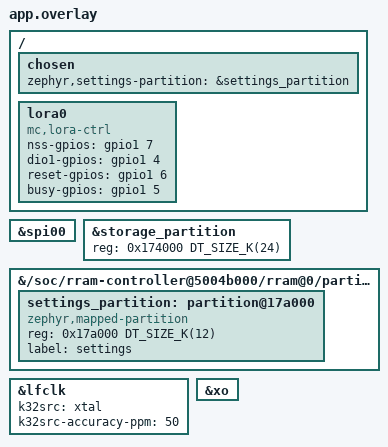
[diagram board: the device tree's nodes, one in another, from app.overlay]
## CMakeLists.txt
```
# Step 4e — full MeshCore companion (companion_radio MyMesh) on the Zephyr seams.
cmake_minimum_required(VERSION 3.20.0)
find_package(Zephyr REQUIRED HINTS $ENV{ZEPHYR_BASE})
project(mc_zephyr_companion)

get_filename_component(MC_ROOT "${CMAKE_CURRENT_SOURCE_DIR}/../.." ABSOLUTE)
set(CR       "${MC_ROOT}/examples/companion_radio")
set(ALFS     "${MC_ROOT}/arch/stm32/Adafruit_LittleFS_stm32/src")
set(RADIOLIB "$ENV{HOME}/Arduino/libraries/RadioLib/src")
set(CRYPTO   "$ENV{HOME}/Arduino/libraries/Crypto/src")
set(CAYENNE  "$ENV{HOME}/Arduino/libraries/CayenneLPP/src")
set(BASE64   "$ENV{HOME}/Arduino/libraries/base64/src")
set(RTCLIB   "$ENV{HOME}/Arduino/libraries/RTClib/src")
set(AJSON    "$ENV{HOME}/Arduino/libraries/ArduinoJson/src")
set(ED25519  "${MC_ROOT}/lib/ed25519")

# MeshCore core + helper set (mirrors the Arduino companion curation)
file(GLOB MC_CORE ${MC_ROOT}/src/*.cpp)
set(MC_HELPERS
  ${MC_ROOT}/src/helpers/BaseChatMesh.cpp
  ${MC_ROOT}/src/helpers/TransportKeyStore.cpp
  ${MC_ROOT}/src/helpers/IdentityStore.cpp
  ${MC_ROOT}/src/helpers/RegionMap.cpp
  ${MC_ROOT}/src/helpers/ClientACL.cpp
  ${MC_ROOT}/src/helpers/CommonCLI.cpp
  ${MC_ROOT}/src/helpers/AdvertDataHelpers.cpp
  ${MC_ROOT}/src/helpers/TxtDataHelpers.cpp
  ${MC_ROOT}/src/helpers/StaticPoolPacketManager.cpp
  ${MC_ROOT}/src/helpers/radiolib/RadioLibWrappers.cpp)

# companion firmware
set(MC_APP ${CR}/MyMesh.cpp ${CR}/DataStore.cpp)

# third-party (generic/non-Arduino mode for RadioLib)
file(GLOB_RECURSE RL_SOURCES ${RADIOLIB}/*.cpp)
list(FILTER RL_SOURCES EXCLUDE REGEX "/hal/Arduino/")
file(GLOB CRYPTO_SRC ${CRYPTO}/*.cpp ${CRYPTO}/*.c)
file(GLOB BASE64_SRC ${BASE64}/*.cpp)
# CayenneLPP + RTClib are shimmed in compat/ (header-only) — real libs pull STL/I2C.
file(GLOB ED_SRC ${ED25519}/*.c)
set(ALFS_SRC ${ALFS}/Adafruit_LittleFS.cpp ${ALFS}/Adafruit_LittleFS_File.cpp
             ${ALFS}/littlefs/lfs.c ${ALFS}/littlefs/lfs_util.c)

target_sources(app PRIVATE
  src/main.cpp src/target.cpp src/zephyr_internal_fs.cpp src/serial_ble_interface.cpp
  ${MC_CORE} ${MC_HELPERS} ${MC_APP}
  ${RL_SOURCES} ${CRYPTO_SRC} ${BASE64_SRC} ${ED_SRC} ${ALFS_SRC})

target_include_directories(app PRIVATE
  compat src ${MC_ROOT}/src ${CR} ${ALFS}
  ${RADIOLIB} ${CRYPTO} ${BASE64} ${ED25519})

target_compile_definitions(app PRIVATE
  NRF54_PLATFORM=1 MESH_DEBUG=1 RADIOLIB_GODMODE=1 MAX_GROUP_CHANNELS=8 MAX_CONTACTS=100 BLE_PIN_CODE=123456
  LFS_NO_ASSERT   # mount-fail (e.g. stale/repartitioned region) -> graceful format, not abort()
  # App TX-power slider max + firmware input check. Pin to the LR2021's absolute (sub-GHz LF)
  # PA ceiling of 22 dBm, INDEPENDENT of the band/boot default, so a 2.4 GHz build still allows
  # 22 once tuned back to sub-GHz. The real per-band limit (HF caps at +12) is enforced at the
  # radio layer by clamp_tx_for_band() in target.cpp. (Otherwise MAX would follow LORA_TX_POWER,
  # which MC_BAND_2G4 sets to 12 -> the app would be stuck at 12 even on 869 MHz.)
  MAX_LORA_TX_POWER=22)

# 2.4 GHz band: build with `-DMC_BAND_2G4=ON` (e.g. west build -- -DMC_BAND_2G4=ON) to boot on
# the LR2021's 2.4 GHz preset (target.h: 2450 MHz / 500 kHz / SF8 / CR5, TX clamped to +12 dBm)
# instead of the default 865 MHz sub-GHz. The app has no 2.4 GHz preset, so this is how to put
# the node on 2.4 GHz for the over-the-air RF test (the choice then persists in prefs).
option(MC_BAND_2G4 "Boot on the 2.4 GHz LoRa preset instead of sub-GHz" OFF)
option(MC_LOW_POWER "Battery build: LR2021 RX duty cycling + sleepy main loop" OFF)
# Side detectors: extra spreading factors the LR2021 receives in parallel on the node's
# channel (comma list, all above the primary SF and within +4; invalid ones are skipped
# when the app changes the SF). A node heard on a side SF is answered on that SF.
set(MC_SIDE_SFS "8" CACHE STRING "LR2021 side-detector SFs, e.g. 8,9,11 (empty = none)")
target_compile_definitions(app PRIVATE MC_SIDE_SFS="${MC_SIDE_SFS}")
if(MC_LOW_POWER)
  target_compile_definitions(app PRIVATE MC_LOW_POWER=1)
endif()
# LoRa boot params must be global -D flags (mirroring platformio.ini), not header
# defines: core headers (e.g. RadioLibWrappers.h getSpreadingFactor) expand LORA_SF
# in translation units that never include target.h. Keep in sync with the presets
# documented in src/target.h.
if(MC_BAND_2G4)
  target_compile_definitions(app PRIVATE MC_BAND_2G4=1
    LORA_FREQ=2450.0f LORA_BW=500.0f LORA_SF=8 LORA_CR=5 LORA_TX_POWER=12)
  message(STATUS "MeshCore: building for 2.4 GHz band (2450 MHz / 500 kHz / SF8 / CR5)")
else()
  target_compile_definitions(app PRIVATE
    LORA_FREQ=869.432f LORA_BW=62.5f LORA_SF=7 LORA_CR=5 LORA_TX_POWER=22)
endif()
```

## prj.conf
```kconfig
# Step 4e — full MeshCore companion on Zephyr.
CONFIG_BT=y
CONFIG_BT_PERIPHERAL=y
CONFIG_BT_DEVICE_NAME="MeshCore"
CONFIG_BT_DEVICE_NAME_DYNAMIC=y
CONFIG_BT_DEVICE_NAME_MAX=40
CONFIG_BT_SMP=y
CONFIG_BT_BONDABLE=y
CONFIG_BT_APP_PASSKEY=y
# BT_MAX_PAIRED defaults to 1 (= BT_MAX_CONN). Phone A bonds -> the single bond slot fills;
# phone B then connects but its (MITM-enforced) pairing has no free slot and FAILS, so B can't
# reach the encryption-gated NUS -> "needs a hard reset to connect another device". Let a new
# pairing recycle the oldest bond instead. (Bonds are RAM-only here, BT_SETTINGS off, so this
# just means each new phone re-pairs cleanly.)
CONFIG_BT_KEYS_OVERWRITE_OLDEST=y
# NUS: we define our own encryption-gated NUS GATT service in serial_ble_interface.cpp
# (so the central drives pairing). Zephyr's built-in NUS is disabled to avoid a duplicate
# service with the same UUIDs.
# CONFIG_BT_ZEPHYR_NUS=y
CONFIG_BT_L2CAP_TX_MTU=247
CONFIG_BT_BUF_ACL_TX_SIZE=251
CONFIG_BT_BUF_ACL_RX_SIZE=251
# At boot the first BLE advertising event collides with the bring-up storm (LR2021 SPI
# init + LittleFS mount + mesh begin), so the SW-split controller's prepare callback runs
# tens of ms late on that one event. BT_CTLR_ASSERT_OVERHEAD_START (default y, a debug aid)
# turns that latency into a FATAL assert (lll_adv.c LL_ASSERT_OVERHEAD), which crashed the
# whole device -- taking the LoRa mesh down with it (no advert RX, looked like a reset loop).
# Disabling it restores the controller's designed behaviour: gracefully skip the delayed
# event (radio_disable + -ECANCELED) and keep running.
# NOTE: ASSERT_OVERHEAD_START lives in the controller's "Advanced features" menu, which is
# `visible if BT_CTLR_ADVANCED_FEATURES`. Without that gate enabled the prompt is hidden and
# a `=n` is silently ignored (symbol stays at its default y). Enable the gate (visibility
# only, no other behaviour change) so the override below actually takes effect.
CONFIG_BT_CTLR_ADVANCED_FEATURES=y
CONFIG_BT_CTLR_ASSERT_OVERHEAD_START=n

CONFIG_FLASH=y
CONFIG_FLASH_MAP=y
# RRAM is byte-alterable and writes (no long erase like NOR flash). The flash driver
# otherwise defaults to RADIO_SYNC_TICKER (because BT_LL_SW_SPLIT), which schedules every
# write into BLE idle timeslots. While connected that dribbles a savePrefs() out one tiny
# window per connection event => a fixed 24s per settings write. Disable radio sync: RRAM
# writes are short enough to run synchronously without disturbing the radio (also bumps the
# RRAM write-buffer 1 -> 32, fewer commits).
CONFIG_SOC_FLASH_NRF_RADIO_SYNC_NONE=y

# Bond persistence DISABLED: on the vanilla open-source controller it broke bonded
# reconnect (phone re-pairs on every reconnect -> disconnect loop) and earlier overflowed
# the bond-save stack. Each connect is a fresh pair (the known-good Android-working flow).
# Robust persistence needs NCS + Nordic SoftDevice Controller (handles bonded-RPA reconnect).
# Persistent bonds on the ZMS backend (RRAM is byte-alterable, no erase - ZMS,
# not NVS, is the settings backend for it), in the 12 KB settings_partition.
CONFIG_BT_SETTINGS=y
CONFIG_SETTINGS=y
CONFIG_FLASH_MAP=y
CONFIG_ZMS=y
CONFIG_SETTINGS_ZMS=y
CONFIG_BT_MAX_PAIRED=3
CONFIG_BT_MAX_CONN=1
CONFIG_BT_SETTINGS_CCC_LAZY_LOADING=y
CONFIG_BT_SETTINGS_CCC_STORE_ON_WRITE=y
# (stacks kept harmless, headroom for the BT/workqueue paths)
CONFIG_BT_RX_STACK_SIZE=8192
CONFIG_SYSTEM_WORKQUEUE_STACK_SIZE=8192

CONFIG_GPIO=y
CONFIG_SPI=y
CONFIG_CPP=y
CONFIG_STD_CPP17=y
CONFIG_CPP_EXCEPTIONS=n
CONFIG_PRINTK=y
CONFIG_CBPRINTF_FP_SUPPORT=y
CONFIG_MAIN_STACK_SIZE=16384
CONFIG_HEAP_MEM_POOL_SIZE=16384
CONFIG_FPU=y
CONFIG_REBOOT=y
CONFIG_ENTROPY_GENERATOR=y

# A fatal error (e.g. the BLE controller assert race) must reboot the node, not halt it.
CONFIG_RESET_ON_FATAL_ERROR=y

# Let the SoC idle between events (the main loop now blocks on a semaphore)
# CONFIG_PM=y  (bisect: suspected of breaking SPI/console once the loop blocks)

# BLE link robustness (2026-09-11): the nRF54L15 radio can do +8 dBm (default 0), and the
# peripheral-preferred supervision timeout defaulted to 420 ms, so any half-second fade at a
# few metres dropped the link and the web app then needed a manual reconnect. 4 s tolerates
# fades; the interval preference (30-50 ms) is unchanged.
CONFIG_BT_CTLR_TX_PWR_PLUS_8=y
CONFIG_BT_PERIPHERAL_PREF_TIMEOUT=400
```

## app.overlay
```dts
/*
 * LR2021 wiring on the XIAO nRF54L15 (matches variants/xiao_nrf54l15/target.h):
 *   SPI  = spi00 (xiao_spi): SCK=P2.1(D8) MOSI=P2.2(D10) MISO=P2.4(D9)
 *   NSS  = P1.7 (D3)   DIO1 = P1.4 (D0)   RESET = P1.6 (D2)   BUSY = P1.5 (D1)
 *
 * RadioLib drives NSS itself (digitalWrite), so the SPI controller is used WITHOUT
 * a hardware CS. The four control pins are plain GPIOs (flags=0 / active-high; the
 * HAL uses raw ops so RadioLib's LOW/HIGH map to physical levels, as on Arduino).
 */
&spi00 {
	status = "okay";
};

/*
 * Split the 36 KB RRAM storage region (0x174000..0x17D000): MeshCore's LittleFS keeps
 * 24 KB; a 12 KB NVS settings partition holds BLE bonds (CONFIG_BT_SETTINGS) so the app
 * doesn't have to re-pair after every reboot.
 */
&storage_partition {
	reg = <0x174000 DT_SIZE_K(24)>;
};

/* add the settings partition as a sibling under the existing fixed-partitions node */
&{/soc/rram-controller@5004b000/rram@0/partitions} {
	settings_partition: partition@17a000 {
		compatible = "zephyr,mapped-partition";
		reg = <0x17a000 DT_SIZE_K(12)>;
		label = "settings";
	};
};

/ {
	chosen {
		zephyr,settings-partition = &settings_partition;
	};

	lora0: lora0 {
		compatible = "mc,lora-ctrl";
		nss-gpios   = <&gpio1 7 0>;
		dio1-gpios  = <&gpio1 4 0>;
		reset-gpios = <&gpio1 6 0>;
		busy-gpios  = <&gpio1 5 0>;
	};
};

/* Zephyr >= 4.5: the BLE controller reads its sleep-clock accuracy from the lfclk
 * node, which the SoC dtsi leaves disabled and the XIAO board files do not enable.
 * The board has a 32.768 kHz crystal (the board dts enables &lfxo). */
&lfclk {
	status = "okay";
	k32src = "xtal";
	k32src-accuracy-ppm = <50>;
};
&xo {
	status = "okay";
};
```

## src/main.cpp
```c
/*
 * Step 4e: the full MeshCore companion on Zephyr. Wires companion_radio's MyMesh +
 * DataStore onto the proven Zephyr seams: radio (target.cpp / RadioLib+ZephyrHal),
 * filesystem (InternalFS / flash_area), and serial = the bonded bt_nus SerialBLEInterface.
 * The phone app pairs (level 4, fixed PIN), then talks the companion protocol over NUS.
 */
#include <zephyr/kernel.h>
#include <zephyr/sys/printk.h>
#include <string.h>
#include <Arduino.h>
#include <target.h>
#include <helpers/nrf54/InternalFileSystem.h>
#include <helpers/SimpleMeshTables.h>
#include "serial_ble_interface.h"
#include "MyMesh.h"   /* examples/companion_radio (on the include path) */

/* Wake-ups for the main loop: the LoRa DIO interrupt and BLE data give this
 * semaphore; otherwise the loop sleeps (MC_LOOP_SLEEP_MS) and the SoC idles. */
K_SEM_DEFINE(mc_wake_sem, 0, 1);
extern "C" void mc_wake(void) { k_sem_give(&mc_wake_sem); }
#ifndef MC_LOOP_SLEEP_MS
#ifdef MC_LOW_POWER
#define MC_LOOP_SLEEP_MS 25
#else
#define MC_LOOP_SLEEP_MS 2
#endif
#endif

SerialShim Serial;

StdRNG fast_rng;
SimpleMeshTables tables;
DataStore store(InternalFS, rtc_clock);

/* Stock MyMesh plus LR2021 time-of-flight ranging (RangingControl.h): answer a
 * neighbour's ranging request as subordinate; range a contact on a private app
 * frame 0xF0 (the BLE interface keeps those aside for us). */
class RangingMesh : public MyMesh {
public:
	using MyMesh::MyMesh;
	RangingRequest defaults{{0, 0, 0, 0}, 2450000000u, 500000, 8, 10, 20438};

	void onControlDataRecv(mesh::Packet* packet) override
	{
		RangingRequest req;
		printk("control packet: type %02x len %u\n", packet->payload[0], packet->payload_len);
		if (rangingDecodeRequest(packet->payload, packet->payload_len, req)) {
			if (memcmp(req.peer, self_id.pub_key, 4) != 0) return;
			printk("ranging: request from a neighbour (%u Hz bw %u sf %u, %u exchanges)\n", req.freq_hz, req.bw_hz, req.sf, req.count);
			NodePrefs* p = getNodePrefs();
			radio_range_subordinate(req, rangingAddrFromPubKey(self_id.pub_key), p->freq, p->bw, p->sf, p->cr);
			return;
		}
		MyMesh::onControlDataRecv(packet);
	}

	void rangeContact(const uint8_t* peer_pubkey, uint8_t count, RangingResult& res)
	{
		RangingRequest req = defaults;
		memcpy(req.peer, peer_pubkey, 4);
		if (count) req.count = count;
		uint8_t payload[RANGING_REQ_LEN];
		rangingEncodeRequest(req, payload);
		mesh::Packet* pkt = createControlData(payload, RANGING_REQ_LEN);
		if (!pkt) { res.status = 3; return; }
		pkt->header &= ~PH_ROUTE_MASK;
		pkt->header |= ROUTE_TYPE_DIRECT;
		pkt->path_len = 0;
		uint8_t raw[MAX_TRANS_UNIT + 8];
		int len = pkt->writeTo(raw);
		releasePacket(pkt);
		if (!radio_driver.startSendRaw(raw, len)) { res.status = 3; return; }
		int64_t t0 = k_uptime_get();
		while (!radio_driver.isSendComplete() && k_uptime_get() - t0 < 2000) { k_msleep(2); }
		radio_driver.onSendFinished();
		k_msleep(RANGING_SETUP_MS);
		NodePrefs* p = getNodePrefs();
		radio_range_manager(req, rangingAddrFromPubKey(peer_pubkey), res, p->freq, p->bw, p->sf, p->cr);
	}
};
RangingMesh the_rmesh(radio_driver, fast_rng, rtc_clock, tables, store);
#define the_mesh the_rmesh

int main(void)
{
	printk("\n=== MeshCore companion on Zephyr (board=%s) ===\n", CONFIG_BOARD);

	board.begin();
	if (!radio_init()) { printk("radio_init FAILED\n"); return 0; }
#ifdef MC_LOW_POWER
	radio_set_low_power(true);
	printk("low-power build: LR2021 RX duty cycling, %d ms loop sleep\n", MC_LOOP_SLEEP_MS);
#endif
	fast_rng.begin(radio_get_rng_seed());
	if (!InternalFS.begin()) { printk("InternalFS FAILED\n"); return 0; }
	store.begin();
	the_mesh.begin(false);   /* no display (loads prefs from /new_prefs) */

	/* DEBUG: did the node name survive the last power cycle? On a cold boot this should show
	 * the previously-set name and exists=1; if it shows the default name / exists=0 the prefs
	 * file was lost (reformat or never persisted). Paired with the "FS: mounted OK/FAILED" line. */
	printk("PREFS: cold boot -> /new_prefs exists=%d, node_name='%s'\n",
	       InternalFS.exists("/new_prefs"), the_mesh.getNodePrefs()->node_name);

	char name[48];
	snprintf(name, sizeof(name), "%s%s", BLE_NAME_PREFIX, the_mesh.getNodePrefs()->node_name);
#ifndef MC_NO_BLE
	ble.begin(name, the_mesh.getBLEPin());
#else
	printk("BLE stack not started (MC_NO_BLE RF interference test build)\n");
#endif
	the_mesh.startInterface(ble);
	printk("companion up: '%s' pin %lu — connect from the MeshCore app\n",
	       name, (unsigned long)the_mesh.getBLEPin());

	while (1) {
		the_mesh.loop();
		{
			uint8_t frame[64];
			size_t n = ble.takePrivateFrame(frame, sizeof(frame));
			if (n >= 34 && frame[0] == RANGING_CMD_CODE) {
				RangingResult res;
				the_mesh.rangeContact(&frame[1], frame[33], res);
				uint8_t out[16];
				ble.writeFrame(out, rangingEncodeResult(res, out));
			}
		}
		rtc_clock.tick();
		sensors.loop();

		/* A rename from the app (CMD_SET_ADVERT_NAME) only updates prefs; push it to BLE so
		 * the advertised/GAP name follows without a reboot. */
		char cur[48];
		snprintf(cur, sizeof(cur), "%s%s", BLE_NAME_PREFIX, the_mesh.getNodePrefs()->node_name);
		if (strcmp(cur, name) != 0) {
			strcpy(name, cur);
			ble.setDeviceName(name);
			/* DEBUG: confirm the rename reached the FS (savePrefs ran in the CMD handler).
			 * exists=1 means /new_prefs was (re)written; if it's still 0 the save never landed. */
			printk("PREFS: rename -> '%s', /new_prefs exists=%d\n",
			       the_mesh.getNodePrefs()->node_name, InternalFS.exists("/new_prefs"));
		}

		k_sem_take(&mc_wake_sem, K_MSEC(MC_LOOP_SLEEP_MS));   /* radio IRQ / BLE data wake us early */
	}
	return 0;
}
```

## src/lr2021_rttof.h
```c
/*
 * LR2021 RTToF (time-of-flight ranging) on top of RadioLib, for the Zephyr
 * companion. Same sequence as lr2021_serial's rng commands / Semtech's USP demo:
 * packet type RTToF, the LoRa modulation re-programmed, the PLL frequency-step
 * register workaround, Tx->Rx delay indicator, then SetTx (manager) or continuous
 * SetRx (subordinate). Distance [m] = raw * 150 / (4096 * BW_MHz).
 */
#pragma once
#include <zephyr/kernel.h>
#include <helpers/radiolib/CustomLR2021.h>
#include "RangingControl.h"

static int16_t rttof_setup(CustomLR2021& r, bool subordinate, uint32_t addr, uint32_t delay, int8_t pwr, uint8_t irq_dio) {
  r.standby();
  int16_t st = r.setPacketType(RADIOLIB_LR2021_PACKET_TYPE_RTTOF);
  if (st == RADIOLIB_ERR_NONE) st = r.setLoRaModulationParams(r.sfCode(), r.bwCode(), r.crCode(), r.ldroCode());
  if (st == RADIOLIB_ERR_NONE) {          // workaround: truncate the PLL frequency step
    uint32_t v = 0; st = r.readRegMem32(0x00F40144, &v, 1);
    if (st == RADIOLIB_ERR_NONE) { v &= ~0x7Fu; st = r.writeRegMem32(0x00F40144, &v, 1); }
  }
  if (st == RADIOLIB_ERR_NONE && !subordinate) st = r.setOutputPower(pwr);
  if (st == RADIOLIB_ERR_NONE) st = r.setLoRaPacketParams(12, RADIOLIB_LRXXXX_LORA_HEADER_EXPLICIT, 7, RADIOLIB_LRXXXX_LORA_CRC_ENABLED, 0);
  if (st == RADIOLIB_ERR_NONE) st = r.setLoRaSyncword(RADIOLIB_LR2021_LORA_SYNC_WORD_PRIVATE);
  uint32_t irq = subordinate ? (RADIOLIB_LR2021_IRQ_TIMEOUT | RADIOLIB_LR2021_IRQ_RNG_REQ_DIS | RADIOLIB_LR2021_IRQ_RNG_RESP_DONE | RADIOLIB_LR2021_IRQ_RNG_REQ_VALID)
                             : (RADIOLIB_LR2021_IRQ_RNG_EXCH_VALID | RADIOLIB_LR2021_IRQ_RNG_TIMEOUT | RADIOLIB_LR2021_IRQ_TIMEOUT);
  if (st == RADIOLIB_ERR_NONE) st = r.setDioIrqConfig(irq_dio, irq);
  if (st == RADIOLIB_ERR_NONE) st = r.setRangingTxRxDelay(delay);
  if (st == RADIOLIB_ERR_NONE) st = r.setRangingParams(false, 15);
  if (st == RADIOLIB_ERR_NONE) st = subordinate ? r.setRangingAddr(addr, 4) : r.setRangingReqAddr(addr);
  if (st == RADIOLIB_ERR_NONE) st = r.clearIrqState(RADIOLIB_LR2021_IRQ_ALL);
  return st;
}

// Apply the ranging radio parameters in LoRa mode first (RadioLib caches the codes).
static int16_t rttof_tune(CustomLR2021& r, const RangingRequest& req, int8_t pwr) {
  r.standby();
  int16_t st = r.setFrequency(req.freq_hz / 1000000.0f);
  if (st == RADIOLIB_ERR_NONE) st = r.setBandwidth(req.bw_hz / 1000.0f);
  if (st == RADIOLIB_ERR_NONE) st = r.setSpreadingFactor(req.sf);
  if (st == RADIOLIB_ERR_NONE) st = r.setCodingRate(5);
  if (st == RADIOLIB_ERR_NONE) st = r.setRxBoostedGainMode(7);   // also selects the band's RX path
  if (st == RADIOLIB_ERR_NONE) st = r.setOutputPower(pwr);        // and the band's PA
  return st;
}

// Answer ranging requests for `window_ms`. Blocks. Leaves the chip in standby, packet type LoRa.
static bool rttof_subordinate(CustomLR2021& r, const RangingRequest& req, uint32_t my_addr, uint8_t irq_dio, uint32_t window_ms, int* answered) {
  int8_t pwr = req.freq_hz > 1500000000u ? 10 : 14;
  if (rttof_tune(r, req, pwr) != RADIOLIB_ERR_NONE) return false;
  if (rttof_setup(r, true, my_addr, req.delay, pwr, irq_dio) != RADIOLIB_ERR_NONE) return false;
  int n = 0;
  int64_t end = k_uptime_get() + window_ms;
  r.setRx(RADIOLIB_LR2021_RX_TIMEOUT_INF);
  while (k_uptime_get() < end) {
    uint32_t irq = r.getIrqFlags();
    if (irq & (RADIOLIB_LR2021_IRQ_RNG_RESP_DONE | RADIOLIB_LR2021_IRQ_RNG_REQ_DIS | RADIOLIB_LR2021_IRQ_TIMEOUT)) {
      if (irq & RADIOLIB_LR2021_IRQ_RNG_RESP_DONE) n++;
      r.clearIrqState(RADIOLIB_LR2021_IRQ_ALL);
      r.setRx(RADIOLIB_LR2021_RX_TIMEOUT_INF);
    }
    k_msleep(2);
  }
  r.standby();
  r.clearTxFifo(); r.clearRxFifo();
  r.setPacketType(RADIOLIB_LR2021_PACKET_TYPE_LORA);
  if (answered) *answered = n;
  return true;
}

// Run `count` exchanges as manager against `peer_addr`. Blocks. Leaves the chip in standby, packet type LoRa.
static bool rttof_manager(CustomLR2021& r, const RangingRequest& req, uint32_t peer_addr, uint8_t irq_dio, RangingResult& res) {
  res = RangingResult(); res.count = req.count;
  int8_t pwr = req.freq_hz > 1500000000u ? 10 : 14;
  if (rttof_tune(r, req, pwr) != RADIOLIB_ERR_NONE || rttof_setup(r, false, peer_addr, req.delay, pwr, irq_dio) != RADIOLIB_ERR_NONE) { res.status = 2; return false; }
  static const uint8_t payload[7] = {0x52, 0x4e, 0x47, 0, 0, 0, 0};
  static int32_t raws[200]; int n = 0;
  float bw_mhz = req.bw_hz / 1000000.0f;
  for (int i = 0; i < req.count && i < 200; i++) {
    r.standby(); r.clearIrqState(RADIOLIB_LR2021_IRQ_ALL);
    r.clearTxFifo();                                  // stale FIFO bytes corrupt the next LoRa TX
    r.writeRadioTxFifo(payload, sizeof(payload));
    if (r.setTx(0) != RADIOLIB_ERR_NONE) break;
    int64_t t0 = k_uptime_get(); uint32_t irq = 0;
    while (k_uptime_get() - t0 < 1500) {
      irq = r.getIrqFlags();
      if (irq & (RADIOLIB_LR2021_IRQ_RNG_EXCH_VALID | RADIOLIB_LR2021_IRQ_RNG_TIMEOUT | RADIOLIB_LR2021_IRQ_TIMEOUT)) break;
      k_msleep(1);
    }
    if (irq & RADIOLIB_LR2021_IRQ_RNG_EXCH_VALID) {
      uint32_t r1 = 0, r2 = 0; uint8_t rs = 0;
      r.getRangingResult(RADIOLIB_LR2021_RANGING_RESULT_TYPE_RAW, &r1, &rs, &r2);
      int32_t v = (int32_t)r1; if (v >= (1 << 23)) v -= (1 << 24);
      raws[n++] = v;
    }
    r.clearIrqState(RADIOLIB_LR2021_IRQ_ALL);
    k_msleep(50);
  }
  r.standby();
  r.clearTxFifo(); r.clearRxFifo();
  r.setPacketType(RADIOLIB_LR2021_PACKET_TYPE_LORA);
  if (!n) { res.status = 1; return false; }
  for (int i = 1; i < n; i++) { int32_t v = raws[i]; int j = i - 1; while (j >= 0 && raws[j] > v) { raws[j + 1] = raws[j]; j--; } raws[j + 1] = v; }
  auto cm = [&](int32_t raw) { return (int32_t)(raw * 150.0f / (4096.0f * bw_mhz) * 100.0f); };
  res.status = 0; res.valid = (uint8_t)n;
  res.median_cm = cm(raws[n / 2]); res.min_cm = cm(raws[0]); res.max_cm = cm(raws[n - 1]);
  return true;
}
```

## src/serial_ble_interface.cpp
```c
#include "serial_ble_interface.h"
extern "C" void mc_wake(void);   /* main loop wake-up (main.cpp) */
#include <zephyr/sys/printk.h>
#include <zephyr/bluetooth/bluetooth.h>
#include <zephyr/bluetooth/conn.h>
#include <zephyr/bluetooth/gatt.h>
#include <zephyr/bluetooth/uuid.h>
#include <zephyr/settings/settings.h>
#include <string.h>

SerialBLEInterface ble;

#ifndef BLE_DBG
#define BLE_DBG(...) printk("BLE: " __VA_ARGS__)
#endif

#ifndef MC_BLE_VERBOSE
#define MC_BLE_VERBOSE 1     /* dump every companion frame in/out */
#endif

#if MC_BLE_VERBOSE
static void mc_dump(const char *dir, const uint8_t *b, uint16_t len)
{
	printk("[%8lld] %s code=%-3u len=%-3u :", (long long)k_uptime_get(), dir, len ? b[0] : 0, len);
	for (uint16_t i = 0; i < len && i < 28; i++) printk(" %02x", b[i]);
	printk("%s\n", len > 28 ? " ..." : "");
}
#else
#define mc_dump(d, b, l)
#endif

/* advertising payload: name + NUS 128-bit UUID (so the MeshCore app finds us).
 * g_ad[1] (the scan-list name) is rewritten at begin() from the runtime node name;
 * CONFIG_BT_DEVICE_NAME is only a placeholder. bt_set_name() sets the GAP Device Name
 * *characteristic* but NOT this advertising payload, so without the rewrite the node
 * always advertised the static "MeshCore" regardless of the configured node name. */
static char g_adv_name[27];   /* 31B adv - 3B flags - 2B AD header => 26 name chars + NUL */
static struct bt_data g_ad[] = {
	BT_DATA_BYTES(BT_DATA_FLAGS, (BT_LE_AD_GENERAL | BT_LE_AD_NO_BREDR)),
	BT_DATA(BT_DATA_NAME_COMPLETE, CONFIG_BT_DEVICE_NAME, sizeof(CONFIG_BT_DEVICE_NAME) - 1),
};
static const struct bt_data g_sd[] = {
	BT_DATA_BYTES(BT_DATA_UUID128_ALL,
		BT_UUID_128_ENCODE(0x6E400001, 0xB5A3, 0xF393, 0xE0A9, 0xE50E24DCCA9E)),
};

/* custom Nordic-UART service, ENCRYPTION-GATED so the *central* drives pairing
 * Zephyr's stock bt_nus characteristics are PERM_NONE, which forced us to send a peripheral
 * SMP Security Request on connect; iOS/Windows respond to that by pairing then dropping &
 * reconnecting. Gating the RX-write and the TX CCC on *authenticated* encryption makes the
 * central initiate MITM (passkey) pairing on first access and stay on the same link. */
static struct bt_uuid_128 nus_srv_uuid = BT_UUID_INIT_128(
	BT_UUID_128_ENCODE(0x6E400001, 0xB5A3, 0xF393, 0xE0A9, 0xE50E24DCCA9E));
static struct bt_uuid_128 nus_tx_uuid = BT_UUID_INIT_128(   /* notify: NODE->APP */
	BT_UUID_128_ENCODE(0x6E400003, 0xB5A3, 0xF393, 0xE0A9, 0xE50E24DCCA9E));
static struct bt_uuid_128 nus_rx_uuid = BT_UUID_INIT_128(   /* write:  APP->NODE */
	BT_UUID_128_ENCODE(0x6E400002, 0xB5A3, 0xF393, 0xE0A9, 0xE50E24DCCA9E));

static ssize_t nus_rx_write(struct bt_conn *conn, const struct bt_gatt_attr *attr,
			    const void *buf, uint16_t len, uint16_t offset, uint8_t flags)
{
	(void)conn; (void)attr; (void)offset; (void)flags;
	ble._onRx(buf, len);
	return len;
}
static void nus_tx_ccc_changed(const struct bt_gatt_attr *attr, uint16_t value) { (void)attr; (void)value; }

/* attrs[0]=svc [1]=TX chrc [2]=TX value [3]=CCC [4]=RX chrc [5]=RX value;
 * notify on attrs[1] (mirrors Zephyr's bt_nus_send). */
BT_GATT_SERVICE_DEFINE(nus_svc,
	BT_GATT_PRIMARY_SERVICE(&nus_srv_uuid),
	BT_GATT_CHARACTERISTIC(&nus_tx_uuid.uuid, BT_GATT_CHRC_NOTIFY,
			       BT_GATT_PERM_NONE, NULL, NULL, NULL),
	BT_GATT_CCC(nus_tx_ccc_changed, BT_GATT_PERM_READ | BT_GATT_PERM_WRITE_AUTHEN),
	BT_GATT_CHARACTERISTIC(&nus_rx_uuid.uuid,
			       BT_GATT_CHRC_WRITE | BT_GATT_CHRC_WRITE_WITHOUT_RESP,
			       BT_GATT_PERM_WRITE_AUTHEN, NULL, nus_rx_write, NULL),
);

/* C BLE callbacks bridging to the single `ble` instance */
static void cb_connected(struct bt_conn *conn, uint8_t err)
{
	if (err) { BLE_DBG("connect failed 0x%02x\n", err); return; }
	BLE_DBG("connected\n");
	ble._onConnect(conn);
	/* Do NOT initiate security here. The NUS characteristics are gated on authenticated
	 * encryption, so the CENTRAL triggers MITM pairing on first access and keeps the link.
	 * A peripheral-initiated Security Request is what made iOS/Windows pair-then-reconnect. */
}
static void cb_disconnected(struct bt_conn *conn, uint8_t reason)
{
	BLE_DBG("disconnected 0x%02x\n", reason);
	ble._onDisconnect(conn);
}
static void cb_security_changed(struct bt_conn *conn, bt_security_t level, enum bt_security_err err)
{
	BLE_DBG("security level %d err %d\n", level, err);
	ble._onSecured(conn, err == BT_SECURITY_ERR_SUCCESS && level >= BT_SECURITY_L2);
}
BT_CONN_CB_DEFINE(conn_cbs) = {
	.connected = cb_connected,
	.disconnected = cb_disconnected,
	.security_changed = cb_security_changed,
};

static void auth_passkey_display(struct bt_conn *conn, unsigned int passkey)
{
	BLE_DBG(">>> enter PASSKEY on phone: %06u <<<\n", passkey);
}
static void auth_cancel(struct bt_conn *conn) { BLE_DBG("pairing cancelled\n"); }
/* Zephyr >= 4.3: the fixed passkey comes from this callback (CONFIG_BT_APP_PASSKEY)
 * instead of the removed bt_passkey_set()/CONFIG_BT_FIXED_PASSKEY. */
static uint32_t s_fixed_passkey = 123456;
static uint32_t auth_app_passkey(struct bt_conn *conn) { return s_fixed_passkey; }
static struct bt_conn_auth_cb auth_cb = {
	.passkey_display = auth_passkey_display,
	.cancel = auth_cancel,
	.app_passkey = auth_app_passkey,
};
static void pairing_complete(struct bt_conn *conn, bool bonded)
{
	BLE_DBG("*** PAIRING COMPLETE bonded=%d ***\n", bonded);
}
static void pairing_failed(struct bt_conn *conn, enum bt_security_err reason)
{
	BLE_DBG("!!! PAIRING FAILED reason=%d !!!\n", reason);
}
static struct bt_conn_auth_info_cb auth_info_cb = {
	.pairing_complete = pairing_complete,
	.pairing_failed = pairing_failed,
};

/* --- SerialBLEInterface impl --- */
void SerialBLEInterface::begin(const char *device_name, uint32_t pin_code)
{
	k_mutex_init(&_lock);
	int err = bt_enable(NULL);
	if (err) { BLE_DBG("bt_enable %d\n", err); return; }

	if (IS_ENABLED(CONFIG_SETTINGS)) {
		settings_load();   /* restore bonds saved by CONFIG_BT_SETTINGS */
	}
	s_fixed_passkey = pin_code;
	bt_conn_auth_cb_register(&auth_cb);
	bt_conn_auth_info_cb_register(&auth_info_cb);
	setDeviceName(device_name);
	BLE_DBG("init done; advertising as '%s' pin %06u\n", bt_get_name(), pin_code);
}

void SerialBLEInterface::setDeviceName(const char *device_name)
{
	if (!device_name || !*device_name) return;
	bt_set_name(device_name);   /* GAP Device Name characteristic (read after connect) */
	/* Mirror the name into the advertising payload (the scan-list name the phone shows),
	 * truncating to the 26-char adv budget. Without this the scan list always read
	 * "MeshCore", and a runtime rename never reached the advertisement at all. The new
	 * g_ad[] is picked up by the next mc_start_adv(); if idle, refresh the live advertisement now. */
	size_t n = strlen(device_name);
	bool shortened = n > sizeof(g_adv_name) - 1;
	if (shortened) n = sizeof(g_adv_name) - 1;
	memcpy(g_adv_name, device_name, n);
	g_adv_name[n] = '\0';
	g_ad[1].type = shortened ? BT_DATA_NAME_SHORTENED : BT_DATA_NAME_COMPLETE;
	g_ad[1].data = (const uint8_t *)g_adv_name;
	g_ad[1].data_len = n;
	BLE_DBG("device name set to '%s'\n", g_adv_name);
	if (_enabled && _conn == nullptr && _advertising) {
		bt_le_adv_update_data(g_ad, ARRAY_SIZE(g_ad), g_sd, ARRAY_SIZE(g_sd));
	}
}

static int mc_start_adv(void)
{
	return bt_le_adv_start(BT_LE_ADV_PARAM(BT_LE_ADV_OPT_CONN,
					       BT_GAP_ADV_FAST_INT_MIN_2,
					       BT_GAP_ADV_FAST_INT_MAX_2, NULL),
			       g_ad, ARRAY_SIZE(g_ad), g_sd, ARRAY_SIZE(g_sd));
}

void SerialBLEInterface::enable()
{
	if (_enabled) return;
	_enabled = true;
	int err = mc_start_adv();
	_advertising = (err == 0);
	BLE_DBG("adv start -> %d\n", err);
}

void SerialBLEInterface::disable()
{
	_enabled = false;
	bt_le_adv_stop();
	if (_conn) bt_conn_disconnect((struct bt_conn *)_conn, BT_HCI_ERR_REMOTE_USER_TERM_CONN);
}

bool SerialBLEInterface::isConnected() const { return _conn != nullptr && _secured; }
bool SerialBLEInterface::isWriteBusy() const { return _send_len >= (QSZ * 2 / 3); }

void SerialBLEInterface::_onConnect(void *conn)
{
	_conn = bt_conn_ref((struct bt_conn *)conn);
	_secured = false;
	_advertising = false;   /* Zephyr stops connectable adv once a connection forms */
	_send_len = 0;
	k_mutex_lock(&_lock, K_FOREVER); _recv_len = 0; k_mutex_unlock(&_lock);
}
void SerialBLEInterface::_onDisconnect(void *conn)
{
	if (_conn) { bt_conn_unref((struct bt_conn *)_conn); _conn = nullptr; }
	_secured = false;
	/* re-advertise is handled in checkRecvFrame() (main thread) avoid BT calls here */
}
void SerialBLEInterface::_onSecured(void *conn, bool ok)
{
	(void)conn;
	_secured = ok;
	/* NOTE: previously requested a conn interval here for Android latency, but an
	 * unsolicited param update right after pairing stalls iOS .
	 * Let the central manage connection parameters. */
}

void SerialBLEInterface::_onRx(const void *data, uint16_t len)
{
	mc_wake();
	if (len == 0 || len > MAX_FRAME_SIZE) return;
	mc_dump("APP->NODE", (const uint8_t *)data, len);
	k_mutex_lock(&_lock, K_FOREVER);
	if (_recv_len < QSZ) {
		_recv[_recv_len].len = len;
		memcpy(_recv[_recv_len].buf, data, len);
		_recv_len++;
	} else {
		printk("BLE: RX queue FULL, dropping frame\n");
	}
	k_mutex_unlock(&_lock);
}

void SerialBLEInterface::shiftSend()
{
	if (_send_len > 0) {
		_send_len--;
		for (uint8_t i = 0; i < _send_len; i++) _send[i] = _send[i + 1];
	}
}

size_t SerialBLEInterface::writeFrame(const uint8_t src[], size_t len)
{
	if (len == 0 || len > MAX_FRAME_SIZE) return 0;
	if (!isConnected() || _send_len >= QSZ) return 0;
	_send[_send_len].len = len;
	memcpy(_send[_send_len].buf, src, len);
	_send_len++;
	return len;
}

size_t SerialBLEInterface::checkRecvFrame(uint8_t dest[])
{
	/* drain queued TX frames over NUS. Push as many as the controller will take this
	 * call (multiple notifications per connection event) instead of one per loop tick;
	 * stop on -ENOMEM (buffers full, retry next call). Speeds up multi-frame answers
	 * (settings/contacts) without touching connection parameters. */
	if (_send_len > 0) {
		if (!isConnected()) {
			_send_len = 0;
		} else {
			while (_send_len > 0) {
				int rc = bt_gatt_notify((struct bt_conn *)_conn, &nus_svc.attrs[1], _send[0].buf, _send[0].len);
				if (rc == 0) { mc_dump("NODE->APP", _send[0].buf, _send[0].len); shiftSend(); }
				else if (rc == -ENOTCONN) { shiftSend(); break; }   /* gone */
				else { printk("BLE: bt_nus_send rc=%d (retry)\n", rc); break; }  /* -ENOMEM: buffers full */
			}
		}
	}
	/* return one received frame; private codes (>= 0xF0, e.g. ranging) are kept
	 * aside for main() rather than handed to MyMesh as an unsupported command */
	size_t out = 0;
	k_mutex_lock(&_lock, K_FOREVER);
	while (_recv_len > 0) {
		Frame f = _recv[0];
		_recv_len--;
		for (uint8_t i = 0; i < _recv_len; i++) _recv[i] = _recv[i + 1];
		if (f.len > 0 && f.buf[0] >= 0xF0) {
			if (!_priv_pending) { _priv = f; _priv_pending = true; }
			continue;
		}
		out = f.len;
		memcpy(dest, f.buf, out);
		break;
	}
	k_mutex_unlock(&_lock);

	/* re-advertise after a disconnect so the app can reconnect without a board reset */
	if (_enabled && _conn == nullptr && !_advertising) {
		unsigned long now = k_uptime_get();
		if (now - _last_adv_try > 500) {        /* throttle retries */
			_last_adv_try = now;
			int rc = mc_start_adv();
			if (rc == 0) {
				_advertising = true;
				BLE_DBG("re-advertising after disconnect\n");
			} else {
				BLE_DBG("re-advertise FAILED rc=%d (will retry)\n", rc);
			}
		}
	}
	return out;
}

size_t SerialBLEInterface::takePrivateFrame(uint8_t dest[], size_t max)
{
	size_t n = 0;
	k_mutex_lock(&_lock, K_FOREVER);
	if (_priv_pending) {
		n = _priv.len < max ? _priv.len : max;
		memcpy(dest, _priv.buf, n);
		_priv_pending = false;
	}
	k_mutex_unlock(&_lock);
	return n;
}
```

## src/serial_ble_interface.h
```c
/*
 * Zephyr SerialBLEInterface: MeshCore's BaseSerialInterface over the Zephyr NUS
 * (bt_nus) + the step-2 bonded pairing (LE SC + MITM + fixed PIN). This is the
 * serial seam the companion role will use; the companion-protocol bytes ride
 * the encrypted, bonded NUS link that the bare-metal core could never establish.
 */
#pragma once
#include <Arduino.h>
#include <helpers/BaseSerialInterface.h>
#include <zephyr/kernel.h>

class SerialBLEInterface : public BaseSerialInterface {
  public:
	/* prefix+name -> advertised name; pin_code = fixed BLE passkey. */
	void begin(const char *device_name, uint32_t pin_code);

	/* Apply (or re-apply at runtime) the BLE name: sets the GAP Device Name characteristic
	 * AND the advertising payload, so a rename takes effect on the next advertise without a
	 * reboot. Safe to call while connected (the new name is used on the next re-advertise). */
	void setDeviceName(const char *device_name);

	void enable() override;
	void disable() override;
	bool isEnabled() const override { return _enabled; }
	bool isConnected() const override;
	bool isWriteBusy() const override;
	size_t writeFrame(const uint8_t src[], size_t len) override;
	size_t checkRecvFrame(uint8_t dest[]) override;
	size_t takePrivateFrame(uint8_t dest[], size_t max);   /* frames with code >= 0xF0 (RangingControl.h) */

	/* invoked from the C BLE callbacks (see .cpp) */
	void _onConnect(void *conn);
	void _onDisconnect(void *conn);
	void _onSecured(void *conn, bool ok);
	void _onRx(const void *data, uint16_t len);

  private:
	struct Frame {
		uint16_t len;
		uint8_t buf[MAX_FRAME_SIZE];
	};
	static const uint8_t QSZ = 12;

	Frame _send[QSZ];
	uint8_t _send_len = 0;          /* main-thread only */
	Frame _recv[QSZ];
	uint8_t _recv_len = 0;          /* filled in BT ctx, read in main -> guarded by _lock */
	Frame _priv;                    /* one pending private (>= 0xF0) frame for main() */
	bool _priv_pending = false;
	struct k_mutex _lock;

	void *_conn = nullptr;          /* struct bt_conn* */
	bool _enabled = false;
	bool _secured = false;
	bool _advertising = false;
	unsigned long _last_adv_try = 0;

	void shiftSend();
};

extern SerialBLEInterface ble;
```

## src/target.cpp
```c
#include "target.h"
#include "zephyr_radiolib_hal.h"
/* Chip quirks (header-CRC standby, RX max-length re-assert) and the mesh wrapper
 * (standby-before-re-arm, RSSI hooks) are shared with the bare-metal variant via
 * CustomLR2021 / CustomLR2021Wrapper — single source for the LR2021 fixes. */
#include <helpers/radiolib/CustomLR2021Wrapper.h>
#include <zephyr/sys/reboot.h>
#include "lr2021_rttof.h"
#include "lr2021_pram.h"

static ZephyrHal hal;

static Module s_mod(&hal, LR_PIN_NSS, LR_PIN_DIO1, LR_PIN_RESET, LR_PIN_BUSY);
static CustomLR2021 s_lora(&s_mod);

ZBoard board;   /* defined before the radio wrapper that references it */

static CustomLR2021Wrapper s_radio(s_lora, board);

/* Sub-GHz PA settings Semtech measured on the Wio-LR2021 (usp_zephyr shield dtsi,
 * tx-power-cfg-lf), indexed by dBm+9 as RadioLib expects. RadioLib's built-in
 * table flattens above +14 dBm on this module and is 5 dB down at +22 (measured
 * with a second kit as monitor); Semtech's keeps 1 dB/dB to the top. */
static LR2021PaTableEntry_t wio_pa_lf[32] = {
  {2, 5, -13}, {6, 1, -13}, {6, 0, -6}, {1, 0, 4},   {2, 0, 4},   {1, 3, 2},   {0, 0, 14}, {0, 3, 9},
  {3, 0, 11},  {1, 0, 16},  {7, 0, 11}, {2, 0, 18},  {5, 0, 16},  {7, 0, 17},  {1, 2, 21}, {3, 0, 25},
  {0, 1, 32},  {2, 0, 32},  {3, 1, 27}, {2, 1, 32},  {5, 1, 28},  {5, 1, 30},  {4, 1, 34}, {5, 4, 31},
  {4, 4, 34},  {5, 6, 34},  {3, 5, 39}, {6, 6, 37},  {5, 5, 40},  {7, 4, 41},  {7, 4, 43}, {7, 7, 44},
};


RadioLibWrapper &radio_driver = s_radio;
VolatileRTCClock rtc_clock;
SensorManager    sensors;

mesh::LocalIdentity radio_new_identity()
{
	RadioNoiseListener rng(s_lora);
	return mesh::LocalIdentity(&rng);   /* new identity from LoRa RSSI noise */
}

void ZBoard::reboot() { sys_reboot(SYS_REBOOT_COLD); }

#define MC_HF_CUTOFF_MHZ  1500.0f

static float  s_freq    = LORA_FREQ;
static int8_t s_req_dbm = LORA_TX_POWER;   /* last app-requested power, pre-clamp */

static int8_t clamp_tx_for_band(float freq, int8_t dbm)
{
	if (freq > MC_HF_CUTOFF_MHZ)                       /* 2.4 GHz HF PA: -19..+12 */
		return dbm > 12 ? 12 : (dbm < -19 ? -19 : dbm);
	return dbm > 22 ? 22 : (dbm < -9 ? -9 : dbm);     /* sub-GHz LF PA: -9..+22 */
}


static bool radio_bringup(float freq, float bw, uint8_t sf, uint8_t cr)
{
	for (int attempt = 0; attempt < 8; attempt++) {

		int16_t st = s_lora.begin(freq, bw, sf, cr,
					  RADIOLIB_LR2021_LORA_SYNC_WORD_PRIVATE,
					  clamp_tx_for_band(freq, s_req_dbm), 16, /*tcxoVoltage=*/0.0f);
		if (st == RADIOLIB_ERR_NONE) {
			/* Semtech's firmware patch RAM (datasheet 22.3): lost on the reset
			 * begin() just did, never loaded by RadioLib */
			uint16_t pram_ver = 0;
			int16_t ps = lr2021_load_pram(s_lora, &pram_ver);
			if (ps == RADIOLIB_ERR_NONE) printk("radio: PRAM loaded, version %u\n", pram_ver);
			else printk("radio: PRAM load failed (%d), continuing without it\n", ps);
			/* match CustomLR2021's proven config: explicit header, CRC, RX boosted gain */
			s_lora.explicitHeader();
			s_lora.setCRC(2);
			s_lora.setRxBoostedGainMode(LR2021_RX_BOOST_LEVEL);
			s_lora._sf = sf; s_lora._bw_khz = bw;     /* begin() bypassed the recording setters */
			int16_t sd = s_lora.applySideDetectors();
			printk("radio: side detectors %u of %u applied (%d)\n", s_lora.appliedSideCount(), s_lora.nSide, sd);
			int16_t rx = s_lora.startReceive();      /* the operation that fails on a bad boot */
			if (rx == RADIOLIB_ERR_NONE) {
				s_lora.standby();                /* idle; the wrapper arms RX in its loop */
				s_freq = freq;
				if (attempt) printk("radio: RX ok after %d retr%s\n",
						    attempt, attempt == 1 ? "y" : "ies");
				return true;
			}
			printk("radio: begin ok but RX arm failed (%d), resetting\n", rx);
		} else {
			printk("radio: begin failed (%d), resetting\n", st);
		}
		s_lora.reset();        /* full chip reset, then retry the whole bring-up */
		k_msleep(50);
	}
	return false;
}

bool radio_init()
{
	s_lora.setIrqDio(LR2021_IRQ_DIO);
	s_lora.setPaTable(wio_pa_lf, false);   /* before begin(): setOutputPower() reads it */
#ifdef MC_SIDE_SFS
	s_lora.setSideSfs(MC_SIDE_SFS);        /* extra SFs received in parallel (build option) */
#endif
	s_freq = LORA_FREQ;
	s_req_dbm = LORA_TX_POWER;
	if (!radio_bringup(LORA_FREQ, LORA_BW, LORA_SF, LORA_CR)) return false;
	s_radio.begin();
	return true;
}

uint32_t radio_get_rng_seed() { return s_lora.random(0x7FFFFFFF); }

void radio_set_params(float freq, float bw, uint8_t sf, uint8_t cr)
{

	bool band_changed = (freq > MC_HF_CUTOFF_MHZ) != (s_freq > MC_HF_CUTOFF_MHZ);
	s_lora.standby();
	int16_t st = s_lora.setFrequency(freq);     /* recalibrates the front-end for the band */
	if (st == RADIOLIB_ERR_NONE) st = s_lora.setBandwidth(bw);
	if (st == RADIOLIB_ERR_NONE) st = s_lora.setSpreadingFactor(sf);
	if (st == RADIOLIB_ERR_NONE) st = s_lora.setCodingRate(cr);
	if (st == RADIOLIB_ERR_NONE) st = s_lora.applySideDetectors();   /* cleared by the setters above */
	s_radio.setCurrentSf(sf);
	s_freq = freq;
	if (band_changed) s_lora.setOutputPower(clamp_tx_for_band(freq, s_req_dbm));
	s_radio.begin();   /* reset wrapper -> dispatcher re-arms RX (startReceive) on the new config */
	if (st != RADIOLIB_ERR_NONE) {
		printk("radio_set_params: apply error %d for %u kHz bw=%u kHz sf%u cr%u\n",
		       st, (unsigned)(freq * 1000.0f), (unsigned)(bw * 1000.0f), sf, cr);
	} else {
		printk("radio_set_params: now on %u kHz bw=%u kHz sf%u cr%u\n",
		       (unsigned)(freq * 1000.0f), (unsigned)(bw * 1000.0f), sf, cr);
	}
}

void radio_set_tx_power(int8_t dbm)
{
	s_req_dbm = dbm;
	s_lora.setOutputPower(clamp_tx_for_band(s_freq, dbm));
}


/* RTToF ranging (RangingControl.h). Both block; afterwards the mesh radio is
 * restored from the given LoRa parameters and the wrapper re-arms RX. */
bool radio_range_subordinate(const RangingRequest& req, uint32_t my_addr, float freq, float bw, uint8_t sf, uint8_t cr)
{
	int answered = 0;
	bool ok = rttof_subordinate(s_lora, req, my_addr, LR2021_IRQ_DIO, rangingWindowMs(req.count), &answered);
	printk("ranging: subordinate window %s, %d responses sent\n", ok ? "done" : "FAILED", answered);
	radio_set_params(freq, bw, sf, cr);
	radio_set_tx_power(s_req_dbm);
	return ok;
}

bool radio_range_manager(const RangingRequest& req, uint32_t peer_addr, RangingResult& res, float freq, float bw, uint8_t sf, uint8_t cr)
{
	bool ok = rttof_manager(s_lora, req, peer_addr, LR2021_IRQ_DIO, res);
	printk("ranging: manager status %u, %u/%u valid, median %d cm (min %d max %d)\n",
	       res.status, res.valid, res.count, res.median_cm, res.min_cm, res.max_cm);
	radio_set_params(freq, bw, sf, cr);
	radio_set_tx_power(s_req_dbm);
	return ok;
}

void radio_set_low_power(bool on)
{
	s_lora.lowPower = on;
	s_radio.begin();   /* wrapper re-arms RX with the new mode */
}
```

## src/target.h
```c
/*
 * Zephyr variant glue for the XIAO nRF54L15 + LR2021: the target.h MeshCore's
 * companion expects (board / radio_driver / rtc_clock / sensors + radio_* funcs +
 * LoRa/BLE config). The concrete radio seam (RadioLib LR2021 + ZephyrHal) lives in
 * target.cpp so its headers (with static-member defs) aren't multiply-included.
 */
#pragma once
#include <Arduino.h>
#include <Mesh.h>
#include <helpers/ArduinoHelpers.h>
#include <helpers/SensorManager.h>
#include <helpers/radiolib/RadioLibWrappers.h>   /* RadioLibWrapper API MyMesh uses */

/* 2.4 GHz preset (LR2021 is dual-band)
 * The RadioLib driver auto-switches to the HF path for any frequency in 2400-2500 MHz;
 * target.cpp clamps TX power to the HF PA max of +12 dBm. NOTE: MeshCore's companion caps
 * bandwidth at 500 kHz, so 812/406 (which the chip supports) are rejected by SET_RADIO_PARAMS. */
#define LORA_FREQ_2G4      2450.0f
#define LORA_BW_2G4        500.0f   /* kHz */
#define LORA_SF_2G4        8
#define LORA_CR_2G4        5
#define LORA_TX_POWER_2G4  12       /* dBm — HF PA maximum */

/* LoRa boot defaults: MeshCore EU sub-GHz canon, unless the build defines MC_BAND_2G4 (see
 * CMakeLists), which boots straight onto the 2.4 GHz preset above. 865 MHz stays the normal
 * build; a 2G4 build needs no app interaction (and the choice persists in prefs). The app
 * has no 2.4 GHz preset of its own, presets are app-side and sub-GHz only, so this flag is
 * the practical way to put the node on 2.4 GHz for the RF test. */
/* NOTE: the real build-time source of these is CMakeLists.txt (global -D flags,
 * mirroring platformio.ini): core headers such as RadioLibWrappers.h expand
 * LORA_SF in translation units that never include this file. The block below is
 * only a fallback for tooling (clangd/IDE) parsing this header standalone. */
#ifdef MC_BAND_2G4
  #ifndef LORA_FREQ
  #define LORA_FREQ      LORA_FREQ_2G4
  #endif
  #ifndef LORA_BW
  #define LORA_BW        LORA_BW_2G4
  #endif
  #ifndef LORA_SF
  #define LORA_SF        LORA_SF_2G4
  #endif
  #ifndef LORA_CR
  #define LORA_CR        LORA_CR_2G4
  #endif
  #ifndef LORA_TX_POWER
  #define LORA_TX_POWER  LORA_TX_POWER_2G4
  #endif
#else
  #ifndef LORA_FREQ
  #define LORA_FREQ      869.618f
  #endif
  #ifndef LORA_BW
  #define LORA_BW        62.5f
  #endif
  #ifndef LORA_SF
  #define LORA_SF        8
  #endif
  #ifndef LORA_CR
  #define LORA_CR        5
  #endif
  #ifndef LORA_TX_POWER
  #define LORA_TX_POWER  22
  #endif
#endif

/* BLE companion */
#ifndef BLE_PIN_CODE
#define BLE_PIN_CODE   123456
#endif
#ifndef BLE_NAME_PREFIX
#define BLE_NAME_PREFIX "MeshCore-"
#endif

class ZBoard : public mesh::MainBoard {
  public:
	void begin() {}
	uint16_t getBattMilliVolts() override { return 0; }
	const char *getManufacturerName() const override { return "XIAO nRF54L15"; }
	void reboot() override;          /* sys_reboot — defined in target.cpp */
	uint8_t getStartupReason() const override { return _reason; }
	uint8_t _reason = 0;
};

extern ZBoard            board;
extern RadioLibWrapper  &radio_driver;   /* concrete LR2021 wrapper bound in target.cpp */
extern VolatileRTCClock  rtc_clock;
extern SensorManager     sensors;

bool radio_init();
uint32_t radio_get_rng_seed();
void radio_set_params(float freq, float bw, uint8_t sf, uint8_t cr);
void radio_set_tx_power(int8_t dbm);
mesh::LocalIdentity radio_new_identity();
void radio_set_low_power(bool on);

#include "RangingControl.h"
bool radio_range_subordinate(const RangingRequest& req, uint32_t my_addr, float freq, float bw, uint8_t sf, uint8_t cr);
bool radio_range_manager(const RangingRequest& req, uint32_t peer_addr, RangingResult& res, float freq, float bw, uint8_t sf, uint8_t cr);
```
